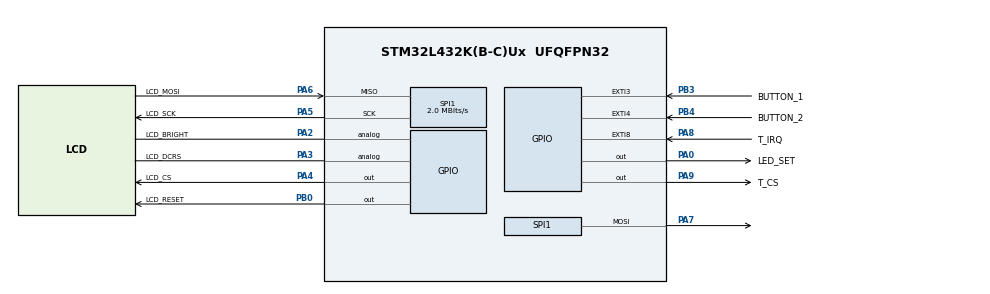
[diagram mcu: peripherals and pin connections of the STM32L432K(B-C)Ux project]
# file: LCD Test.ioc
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Mcu.Family=STM32L4
Mcu.Name=STM32L432K(B-C)Ux
Mcu.Package=UFQFPN32
NVIC.PriorityGroup=NVIC_PRIORITYGROUP_4
PA0.GPIO_Label=LED_SET
PA0.Signal=GPIO_Output
PA13\ (JTMS-SWDIO).Mode=Serial_Wire
PA13\ (JTMS-SWDIO).Signal=SYS_JTMS-SWDIO
PA14\ (JTCK-SWCLK).Mode=Serial_Wire
PA14\ (JTCK-SWCLK).Signal=SYS_JTCK-SWCLK
PA2.GPIO_Label=LCD_BRIGHT
PA2.Signal=GPIO_Analog
PA3.GPIO_Label=LCD_DCRS
PA3.Signal=GPIO_Analog
PA4.GPIO_Label=LCD_CS
PA4.PinState=GPIO_PIN_SET
PA4.Signal=GPIO_Output
PA5.GPIO_Label=LCD_SCK
PA5.Mode=Full_Duplex_Master
PA5.Signal=SPI1_SCK
PA6.GPIO_Label=LCD_MOSI
PA6.Mode=Full_Duplex_Master
PA6.Signal=SPI1_MISO
PA7.Mode=Full_Duplex_Master
PA7.Signal=SPI1_MOSI
PA8.GPIO_Label=T_IRQ
PA8.Signal=GPXTI8
PA9.GPIO_Label=T_CS
PA9.Signal=GPIO_Output
PB0.GPIO_Label=LCD_RESET
PB0.Signal=GPIO_Output
PB3\ (JTDO-TRACESWO).GPIO_Label=BUTTON_1
PB3\ (JTDO-TRACESWO).Signal=GPXTI3
PB4\ (NJTRST).GPIO_Label=BUTTON_2
PB4\ (NJTRST).Signal=GPXTI4
ProjectManager.HeapSize=0x200
ProjectManager.StackSize=0x400
ProjectManager.TargetToolchain=STM32CubeIDE
RCC.HSE_VALUE=8000000
RCC.HSI48_VALUE=48000000
RCC.HSI_VALUE=16000000
RCC.LSE_VALUE=32768
RCC.MSI_VALUE=4000000
RCC.VCOOutputFreq_Value=32000000
SPI1.CalculateBaudRate=2.0 MBits/s
SPI1.Direction=SPI_DIRECTION_2LINES
SPI1.Mode=SPI_MODE_MASTER
SPI1.VirtualType=VM_MASTER
board=custom

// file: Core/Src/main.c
/* USER CODE BEGIN Header */
/**
  ******************************************************************************
  * @file           : main.c
  * @brief          : Main program body
  ******************************************************************************
  * @attention
  *
  * Copyright (c) 2025 STMicroelectronics.
  * All rights reserved.
  *
  * This software is licensed under terms that can be found in the LICENSE file
  * in the root directory of this software component.
  * If no LICENSE file comes with this software, it is provided AS-IS.
  *
  ******************************************************************************
  */
/* USER CODE END Header */
#include "main.h"

/* USER CODE BEGIN Includes */

#include "stm32_adafruit_lcd.h"

/* USER CODE END Includes */

SPI_HandleTypeDef hspi1;

void SystemClock_Config(void);
static void MX_GPIO_Init(void);
static void MX_SPI1_Init(void);

int main(void)
{

  /* MCU Configuration--------------------------------------------------------*/

  /* Reset of all peripherals, Initializes the Flash interface and the Systick. */
  HAL_Init();

  /* Configure the system clock */
  SystemClock_Config();

  /* Initialize all configured peripherals */
  MX_GPIO_Init();
  MX_SPI1_Init();
  /* USER CODE BEGIN 2 */

  BSP_LCD_Init();

  /* USER CODE END 2 */

  /* Infinite loop */
  /* USER CODE BEGIN WHILE */
  while (1)
  {
//	  BSP_LCD_Clear(LCD_COLOR_BLUE);
//  HAL_GPIO_WritePin(LCD_CS_GPIO_Port, LCD_CS_Pin, GPIO_PIN_RESET);
//	  uint8_t TX_Buffer = 8; // DATA to send
//	  uint8_t a = HAL_SPI_Transmit(&hspi1, &TX_Buffer, 1, 1000); //Sending in Blocking mode
//  HAL_GPIO_WritePin(LCD_CS_GPIO_Port, LCD_CS_Pin, GPIO_PIN_SET);
//
	  HAL_Delay(10);
    /* USER CODE END WHILE */

  }
}

void SystemClock_Config(void)
{
  RCC_OscInitTypeDef RCC_OscInitStruct = {0};
  RCC_ClkInitTypeDef RCC_ClkInitStruct = {0};

  /** Configure the main internal regulator output voltage
  */
  if (HAL_PWREx_ControlVoltageScaling(PWR_REGULATOR_VOLTAGE_SCALE1) != HAL_OK)
  {
    Error_Handler();
  }

  /** Initializes the RCC Oscillators according to the specified parameters
  * in the RCC_OscInitTypeDef structure.
  */
  RCC_OscInitStruct.OscillatorType = RCC_OSCILLATORTYPE_MSI;
  RCC_OscInitStruct.MSIState = RCC_MSI_ON;
  RCC_OscInitStruct.MSICalibrationValue = 0;
  RCC_OscInitStruct.MSIClockRange = RCC_MSIRANGE_6;
  RCC_OscInitStruct.PLL.PLLState = RCC_PLL_NONE;
  if (HAL_RCC_OscConfig(&RCC_OscInitStruct) != HAL_OK)
  {
    Error_Handler();
  }

  /** Initializes the CPU, AHB and APB buses clocks
  */
  RCC_ClkInitStruct.ClockType = RCC_CLOCKTYPE_HCLK|RCC_CLOCKTYPE_SYSCLK
                              |RCC_CLOCKTYPE_PCLK1|RCC_CLOCKTYPE_PCLK2;
  RCC_ClkInitStruct.SYSCLKSource = RCC_SYSCLKSOURCE_MSI;
  RCC_ClkInitStruct.AHBCLKDivider = RCC_SYSCLK_DIV1;
  RCC_ClkInitStruct.APB1CLKDivider = RCC_HCLK_DIV1;
  RCC_ClkInitStruct.APB2CLKDivider = RCC_HCLK_DIV1;

  if (HAL_RCC_ClockConfig(&RCC_ClkInitStruct, FLASH_LATENCY_0) != HAL_OK)
  {
    Error_Handler();
  }
}

static void MX_SPI1_Init(void)
{

  /* SPI1 parameter configuration*/
  hspi1.Instance = SPI1;
  hspi1.Init.Mode = SPI_MODE_MASTER;
  hspi1.Init.Direction = SPI_DIRECTION_2LINES;
  hspi1.Init.DataSize = SPI_DATASIZE_4BIT;
  hspi1.Init.CLKPolarity = SPI_POLARITY_LOW;
  hspi1.Init.CLKPhase = SPI_PHASE_1EDGE;
  hspi1.Init.NSS = SPI_NSS_SOFT;
  hspi1.Init.BaudRatePrescaler = SPI_BAUDRATEPRESCALER_2;
  hspi1.Init.FirstBit = SPI_FIRSTBIT_MSB;
  hspi1.Init.TIMode = SPI_TIMODE_DISABLE;
  hspi1.Init.CRCCalculation = SPI_CRCCALCULATION_DISABLE;
  hspi1.Init.CRCPolynomial = 7;
  hspi1.Init.CRCLength = SPI_CRC_LENGTH_DATASIZE;
  hspi1.Init.NSSPMode = SPI_NSS_PULSE_ENABLE;
  if (HAL_SPI_Init(&hspi1) != HAL_OK)
  {
    Error_Handler();
  }

}

static void MX_GPIO_Init(void)
{
  GPIO_InitTypeDef GPIO_InitStruct = {0};

  /* GPIO Ports Clock Enable */
  __HAL_RCC_GPIOA_CLK_ENABLE();
  __HAL_RCC_GPIOB_CLK_ENABLE();

  /*Configure GPIO pin Output Level */
  HAL_GPIO_WritePin(GPIOA, LED_SET_Pin|T_CS_Pin, GPIO_PIN_RESET);

  /*Configure GPIO pin Output Level */
  HAL_GPIO_WritePin(LCD_CS_GPIO_Port, LCD_CS_Pin, GPIO_PIN_SET);

  /*Configure GPIO pin Output Level */
  HAL_GPIO_WritePin(LCD_RESET_GPIO_Port, LCD_RESET_Pin, GPIO_PIN_RESET);

  /*Configure GPIO pins : LED_SET_Pin LCD_CS_Pin T_CS_Pin */
  GPIO_InitStruct.Pin = LED_SET_Pin|LCD_CS_Pin|T_CS_Pin;
  GPIO_InitStruct.Mode = GPIO_MODE_OUTPUT_PP;
  GPIO_InitStruct.Pull = GPIO_NOPULL;
  GPIO_InitStruct.Speed = GPIO_SPEED_FREQ_LOW;
  HAL_GPIO_Init(GPIOA, &GPIO_InitStruct);

  /*Configure GPIO pins : LCD_BRIGHT_Pin LCD_DCRS_Pin */
  GPIO_InitStruct.Pin = LCD_BRIGHT_Pin|LCD_DCRS_Pin;
  GPIO_InitStruct.Mode = GPIO_MODE_ANALOG;
  GPIO_InitStruct.Pull = GPIO_NOPULL;
  HAL_GPIO_Init(GPIOA, &GPIO_InitStruct);

  /*Configure GPIO pin : LCD_RESET_Pin */
  GPIO_InitStruct.Pin = LCD_RESET_Pin;
  GPIO_InitStruct.Mode = GPIO_MODE_OUTPUT_PP;
  GPIO_InitStruct.Pull = GPIO_NOPULL;
  GPIO_InitStruct.Speed = GPIO_SPEED_FREQ_LOW;
  HAL_GPIO_Init(LCD_RESET_GPIO_Port, &GPIO_InitStruct);

  /*Configure GPIO pin : T_IRQ_Pin */
  GPIO_InitStruct.Pin = T_IRQ_Pin;
  GPIO_InitStruct.Mode = GPIO_MODE_IT_RISING;
  GPIO_InitStruct.Pull = GPIO_NOPULL;
  HAL_GPIO_Init(T_IRQ_GPIO_Port, &GPIO_InitStruct);

  /*Configure GPIO pins : BUTTON_1_Pin BUTTON_2_Pin */
  GPIO_InitStruct.Pin = BUTTON_1_Pin|BUTTON_2_Pin;
  GPIO_InitStruct.Mode = GPIO_MODE_IT_RISING;
  GPIO_InitStruct.Pull = GPIO_NOPULL;
  HAL_GPIO_Init(GPIOB, &GPIO_InitStruct);

}

void Error_Handler(void)
{
  __disable_irq();
  while (1)
  {
  }
}
